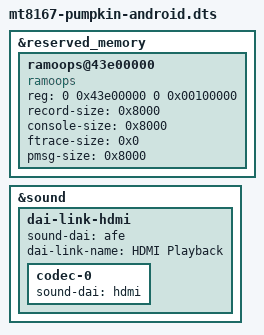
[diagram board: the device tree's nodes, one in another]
/dts-v1/;
/plugin/;

#include <dt-bindings/clock/mt8167-clk.h>
#include <dt-bindings/interrupt-controller/arm-gic.h>
#include <dt-bindings/interrupt-controller/irq.h>

#include "mt8516-pinfunc.h"
#include "mt8167-pinfunc.h"

&reserved_memory {
	#address-cells = <2>;
	#size-cells = <2>;

	ramoops@43e00000 {
		compatible = "ramoops";
		reg = <0 0x43e00000 0 0x00100000>;
		record-size = <0x8000>;
		console-size = <0x8000>;
		ftrace-size = <0x0>;
		pmsg-size = <0x8000>;
	};
};

&sound {
	dai-link-hdmi {
		sound-dai = <&afe>;
		dai-link-name = "HDMI Playback";

		codec-0 {
			sound-dai = <&hdmi>;
		};
	};
};
